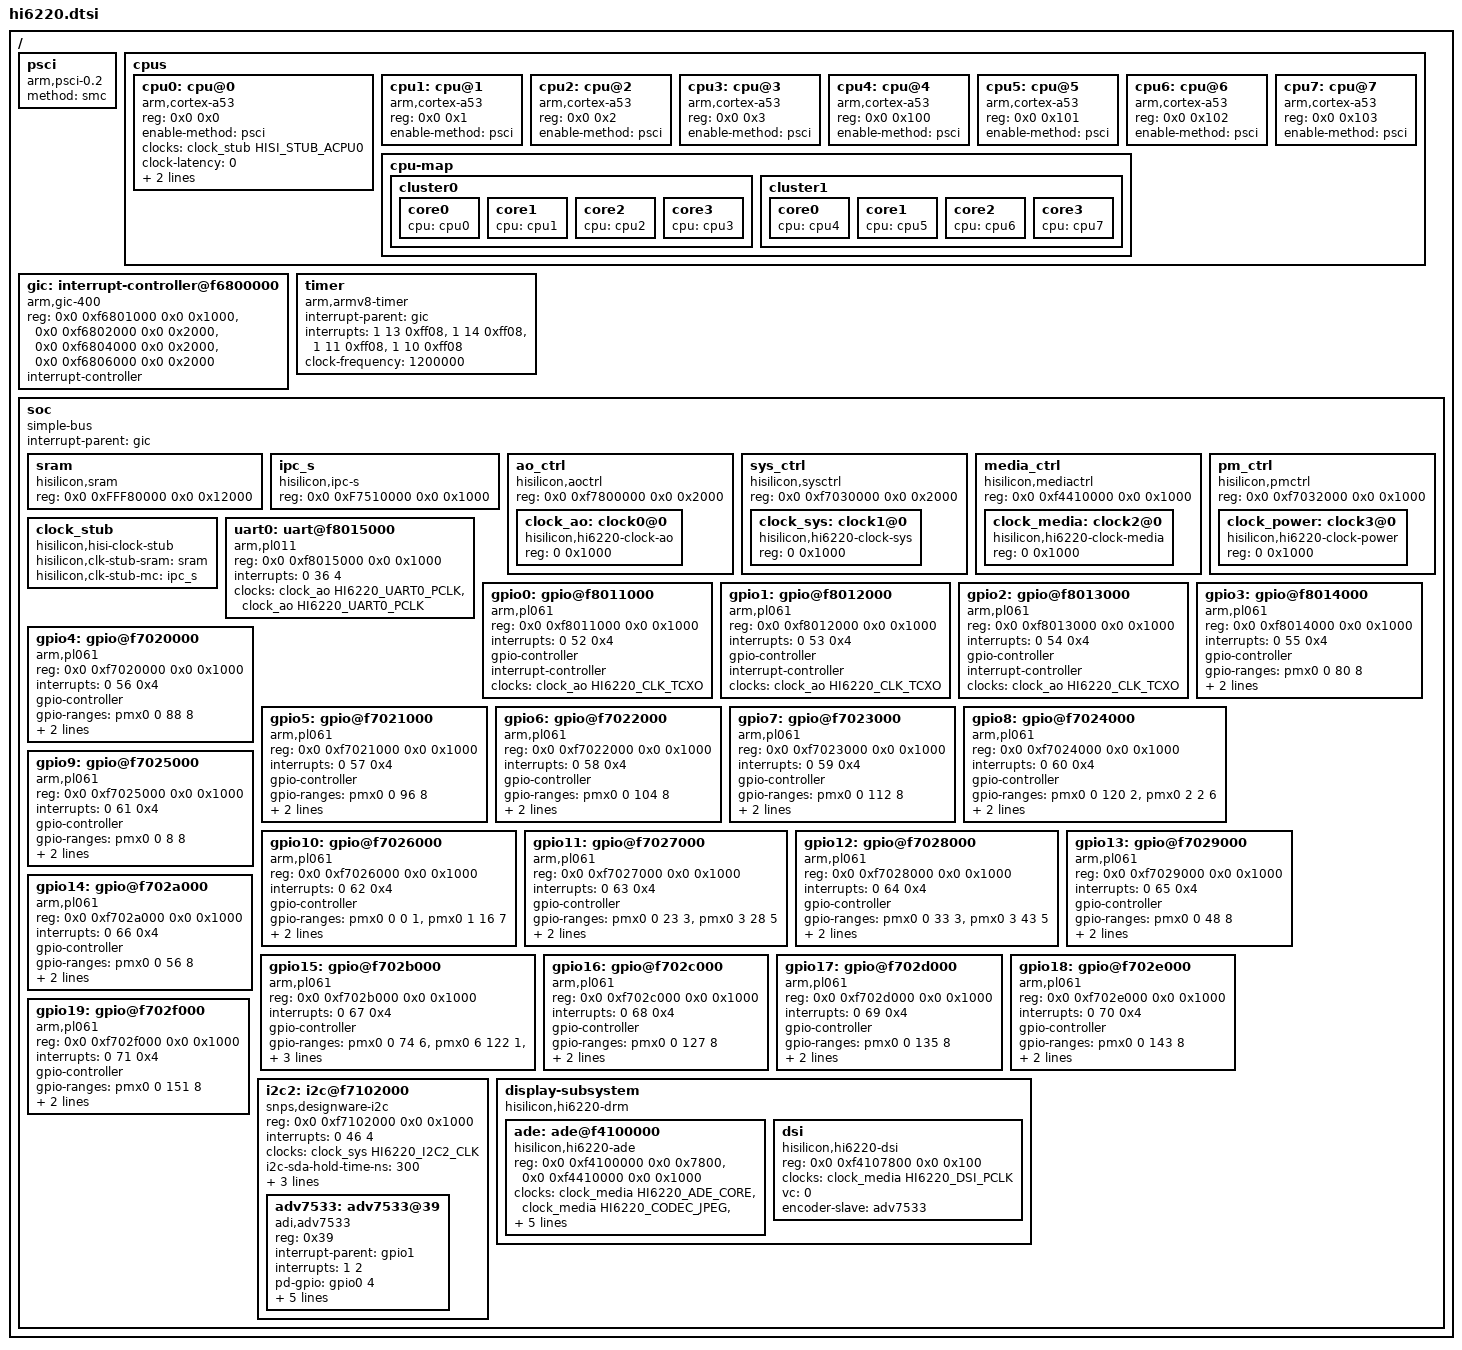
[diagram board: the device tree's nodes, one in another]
/*
 * dts file for Hisilicon Hi6220 SoC
 *
 * Copyright (C) 2015, Hisilicon Ltd.
 */

#include <dt-bindings/clock/hi6220-clock.h>

/ {
	psci {
		compatible = "arm,psci-0.2";
		method = "smc";
	};

	cpus {
		#address-cells = <2>;
		#size-cells = <0>;

		cpu0: cpu@0 {
			compatible = "arm,cortex-a53", "arm,armv8";
			device_type = "cpu";
			reg = <0x0 0x0>;
			enable-method = "psci";
			clocks = <&clock_stub HISI_STUB_ACPU0>;
			clock-latency = <0>;
			operating-points = <
				/* kHz */
				1200000  0
				960000   0
				729000   0
				432000   0
				208000   0
			>;
			#cooling-cells = <2>; /* min followed by max */
		};

		cpu1: cpu@1 {
			compatible = "arm,cortex-a53", "arm,armv8";
			device_type = "cpu";
			reg = <0x0 0x1>;
			enable-method = "psci";
		};

		cpu2: cpu@2 {
			compatible = "arm,cortex-a53", "arm,armv8";
			device_type = "cpu";
			reg = <0x0 0x2>;
			enable-method = "psci";
		};

		cpu3: cpu@3 {
			compatible = "arm,cortex-a53", "arm,armv8";
			device_type = "cpu";
			reg = <0x0 0x3>;
			enable-method = "psci";
		};

		cpu4: cpu@4 {
			compatible = "arm,cortex-a53", "arm,armv8";
			device_type = "cpu";
			reg = <0x0 0x100>;
			enable-method = "psci";
		};

		cpu5: cpu@5 {
			compatible = "arm,cortex-a53", "arm,armv8";
			device_type = "cpu";
			reg = <0x0 0x101>;
			enable-method = "psci";
		};

		cpu6: cpu@6 {
			compatible = "arm,cortex-a53", "arm,armv8";
			device_type = "cpu";
			reg = <0x0 0x102>;
			enable-method = "psci";
		};

		cpu7: cpu@7 {
			compatible = "arm,cortex-a53", "arm,armv8";
			device_type = "cpu";
			reg = <0x0 0x103>;
			enable-method = "psci";
		};

		cpu-map {
			cluster0 {
				core0 {
					cpu = <&cpu0>;
				};
				core1 {
					cpu = <&cpu1>;
				};
				core2 {
					cpu = <&cpu2>;
				};
				core3 {
					cpu = <&cpu3>;
				};
			};
			cluster1 {
				core0 {
					cpu = <&cpu4>;
				};
				core1 {
					cpu = <&cpu5>;
				};
				core2 {
					cpu = <&cpu6>;
				};
				core3 {
					cpu = <&cpu7>;
				};
			};
		};
	};

	gic: interrupt-controller@f6800000 {
		compatible = "arm,gic-400", "arm,cortex-a15-gic";
		reg = <0x0 0xf6801000 0x0 0x1000>, /* GICD */
		      <0x0 0xf6802000 0x0 0x2000>, /* GICC */
		      <0x0 0xf6804000 0x0 0x2000>, /* GICH */
		      <0x0 0xf6806000 0x0 0x2000>; /* GICV */
		#interrupt-cells = <3>;
		#address-cells = <0>;
		interrupt-controller;
	};


	timer {
		compatible = "arm,armv8-timer";
		interrupt-parent = <&gic>;
		interrupts = <1 13 0xff08>,
			     <1 14 0xff08>,
			     <1 11 0xff08>,
			     <1 10 0xff08>;
		clock-frequency = <1200000>;
	};

	soc {
		compatible = "simple-bus";
		#address-cells = <2>;
		#size-cells = <2>;
		interrupt-parent = <&gic>;
		ranges;

		sram: sram {
			compatible = "hisilicon,sram", "syscon";
			reg = <0x0 0xFFF80000 0x0 0x12000>;
		};

		ipc_s: ipc_s {
			compatible = "hisilicon,ipc-s", "syscon";
			reg = <0x0 0xF7510000 0x0 0x1000>;
		};

		ao_ctrl: ao_ctrl {
			compatible = "hisilicon,aoctrl", "syscon";
			#address-cells = <1>;
			#size-cells = <1>;
			reg = <0x0 0xf7800000 0x0 0x2000>;
			ranges = <0 0x0 0xf7800000 0x2000>;

			clock_ao: clock0@0 {
				compatible = "hisilicon,hi6220-clock-ao";
				reg = <0 0x1000>;
				#clock-cells = <1>;
			};
		};

		sys_ctrl: sys_ctrl {
			compatible = "hisilicon,sysctrl", "syscon";
			#address-cells = <1>;
			#size-cells = <1>;
			reg = <0x0 0xf7030000 0x0 0x2000>;
			ranges = <0 0x0 0xf7030000 0x2000>;

			clock_sys: clock1@0 {
				compatible = "hisilicon,hi6220-clock-sys";
				reg = <0 0x1000>;
				#clock-cells = <1>;
			};
		};

		media_ctrl: media_ctrl {
			compatible = "hisilicon,mediactrl", "syscon";
			#address-cells = <1>;
			#size-cells = <1>;
			reg = <0x0 0xf4410000 0x0 0x1000>;
			ranges = <0 0x0 0xf4410000 0x1000>;

			clock_media: clock2@0 {
				compatible = "hisilicon,hi6220-clock-media";
				reg = <0 0x1000>;
				#clock-cells = <1>;
			};
		};

		pm_ctrl: pm_ctrl {
			compatible = "hisilicon,pmctrl", "syscon";
			#address-cells = <1>;
			#size-cells = <1>;
			reg = <0x0 0xf7032000 0x0 0x1000>;
			ranges = <0 0x0 0xf7032000 0x1000>;

			clock_power: clock3@0 {
				compatible = "hisilicon,hi6220-clock-power";
				reg = <0 0x1000>;
				#clock-cells = <1>;
			};
		};

		clock_stub: clock_stub {
			compatible = "hisilicon,hisi-clock-stub";
			hisilicon,clk-stub-sram = <&sram>;
			hisilicon,clk-stub-mc = <&ipc_s>;
			#clock-cells = <1>;
		};

		uart0: uart@f8015000 {	/* console */
			compatible = "arm,pl011", "arm,primecell";
			reg = <0x0 0xf8015000 0x0 0x1000>;
			interrupts = <0 36 4>;
			clocks = <&clock_ao HI6220_UART0_PCLK>, <&clock_ao HI6220_UART0_PCLK>;
			clock-names = "uartclk", "apb_pclk";
		};

		gpio0: gpio@f8011000 {
			compatible = "arm,pl061", "arm,primecell";
			reg = <0x0 0xf8011000 0x0 0x1000>;
			interrupts = <0 52 0x4>;
			gpio-controller;
			#gpio-cells = <2>;
			interrupt-controller;
			#interrupt-cells = <2>;
			clocks = <&clock_ao HI6220_CLK_TCXO>;
			clock-names = "apb_pclk";
			status = "ok";
		};

		gpio1: gpio@f8012000 {
			compatible = "arm,pl061", "arm,primecell";
			reg = <0x0 0xf8012000 0x0 0x1000>;
			interrupts = <0 53 0x4>;
			gpio-controller;
			#gpio-cells = <2>;
			interrupt-controller;
			#interrupt-cells = <2>;
			clocks = <&clock_ao HI6220_CLK_TCXO>;
			clock-names = "apb_pclk";
			status = "ok";
		};

		gpio2: gpio@f8013000 {
			compatible = "arm,pl061", "arm,primecell";
			reg = <0x0 0xf8013000 0x0 0x1000>;
			interrupts = <0 54 0x4>;
			gpio-controller;
			#gpio-cells = <2>;
			interrupt-controller;
			#interrupt-cells = <2>;
			clocks = <&clock_ao HI6220_CLK_TCXO>;
			clock-names = "apb_pclk";
			status = "ok";
		};

		gpio3: gpio@f8014000 {
			compatible = "arm,pl061", "arm,primecell";
			reg = <0x0 0xf8014000 0x0 0x1000>;
			interrupts = <0 55 0x4>;
			gpio-controller;
			#gpio-cells = <2>;
			gpio-ranges = <&pmx0 0 80 8>;
			interrupt-controller;
			#interrupt-cells = <2>;
			clocks = <&clock_ao HI6220_CLK_TCXO>;
			clock-names = "apb_pclk";
			status = "ok";
		};

		gpio4: gpio@f7020000 {
			compatible = "arm,pl061", "arm,primecell";
			reg = <0x0 0xf7020000 0x0 0x1000>;
			interrupts = <0 56 0x4>;
			gpio-controller;
			#gpio-cells = <2>;
			gpio-ranges = <&pmx0 0 88 8>;
			interrupt-controller;
			#interrupt-cells = <2>;
			clocks = <&clock_ao HI6220_CLK_TCXO>;
			clock-names = "apb_pclk";
			status = "ok";
		};

		gpio5: gpio@f7021000 {
			compatible = "arm,pl061", "arm,primecell";
			reg = <0x0 0xf7021000 0x0 0x1000>;
			interrupts = <0 57 0x4>;
			gpio-controller;
			#gpio-cells = <2>;
			gpio-ranges = <&pmx0 0 96 8>;
			interrupt-controller;
			#interrupt-cells = <2>;
			clocks = <&clock_ao HI6220_CLK_TCXO>;
			clock-names = "apb_pclk";
			status = "ok";
		};

		gpio6: gpio@f7022000 {
			compatible = "arm,pl061", "arm,primecell";
			reg = <0x0 0xf7022000 0x0 0x1000>;
			interrupts = <0 58 0x4>;
			gpio-controller;
			#gpio-cells = <2>;
			gpio-ranges = <&pmx0 0 104 8>;
			interrupt-controller;
			#interrupt-cells = <2>;
			clocks = <&clock_ao HI6220_CLK_TCXO>;
			clock-names = "apb_pclk";
			status = "ok";
		};

		gpio7: gpio@f7023000 {
			compatible = "arm,pl061", "arm,primecell";
			reg = <0x0 0xf7023000 0x0 0x1000>;
			interrupts = <0 59 0x4>;
			gpio-controller;
			#gpio-cells = <2>;
			gpio-ranges = <&pmx0 0 112 8>;
			interrupt-controller;
			#interrupt-cells = <2>;
			clocks = <&clock_ao HI6220_CLK_TCXO>;
			clock-names = "apb_pclk";
			status = "ok";
		};

		gpio8: gpio@f7024000 {
			compatible = "arm,pl061", "arm,primecell";
			reg = <0x0 0xf7024000 0x0 0x1000>;
			interrupts = <0 60 0x4>;
			gpio-controller;
			#gpio-cells = <2>;
			gpio-ranges = <&pmx0 0 120 2 &pmx0 2 2 6>;
			interrupt-controller;
			#interrupt-cells = <2>;
			clocks = <&clock_ao HI6220_CLK_TCXO>;
			clock-names = "apb_pclk";
			status = "ok";
		};

		gpio9: gpio@f7025000 {
			compatible = "arm,pl061", "arm,primecell";
			reg = <0x0 0xf7025000 0x0 0x1000>;
			interrupts = <0 61 0x4>;
			gpio-controller;
			#gpio-cells = <2>;
			gpio-ranges = <&pmx0 0 8 8>;
			interrupt-controller;
			#interrupt-cells = <2>;
			clocks = <&clock_ao HI6220_CLK_TCXO>;
			clock-names = "apb_pclk";
			status = "ok";
		};

		gpio10: gpio@f7026000 {
			compatible = "arm,pl061", "arm,primecell";
			reg = <0x0 0xf7026000 0x0 0x1000>;
			interrupts = <0 62 0x4>;
			gpio-controller;
			#gpio-cells = <2>;
			gpio-ranges = <&pmx0 0 0 1 &pmx0 1 16 7>;
			interrupt-controller;
			#interrupt-cells = <2>;
			clocks = <&clock_ao HI6220_CLK_TCXO>;
			clock-names = "apb_pclk";
			status = "ok";
		};

		gpio11: gpio@f7027000 {
			compatible = "arm,pl061", "arm,primecell";
			reg = <0x0 0xf7027000 0x0 0x1000>;
			interrupts = <0 63 0x4>;
			gpio-controller;
			#gpio-cells = <2>;
			gpio-ranges = <&pmx0 0 23 3 &pmx0 3 28 5>;
			interrupt-controller;
			#interrupt-cells = <2>;
			clocks = <&clock_ao HI6220_CLK_TCXO>;
			clock-names = "apb_pclk";
			status = "ok";
		};

		gpio12: gpio@f7028000 {
			compatible = "arm,pl061", "arm,primecell";
			reg = <0x0 0xf7028000 0x0 0x1000>;
			interrupts = <0 64 0x4>;
			gpio-controller;
			#gpio-cells = <2>;
			gpio-ranges = <&pmx0 0 33 3 &pmx0 3 43 5>;
			interrupt-controller;
			#interrupt-cells = <2>;
			clocks = <&clock_ao HI6220_CLK_TCXO>;
			clock-names = "apb_pclk";
			status = "ok";
		};

		gpio13: gpio@f7029000 {
			compatible = "arm,pl061", "arm,primecell";
			reg = <0x0 0xf7029000 0x0 0x1000>;
			interrupts = <0 65 0x4>;
			gpio-controller;
			#gpio-cells = <2>;
			gpio-ranges = <&pmx0 0 48 8>;
			interrupt-controller;
			#interrupt-cells = <2>;
			clocks = <&clock_ao HI6220_CLK_TCXO>;
			clock-names = "apb_pclk";
			status = "ok";
		};

		gpio14: gpio@f702a000 {
			compatible = "arm,pl061", "arm,primecell";
			reg = <0x0 0xf702a000 0x0 0x1000>;
			interrupts = <0 66 0x4>;
			gpio-controller;
			#gpio-cells = <2>;
			gpio-ranges = <&pmx0 0 56 8>;
			interrupt-controller;
			#interrupt-cells = <2>;
			clocks = <&clock_ao HI6220_CLK_TCXO>;
			clock-names = "apb_pclk";
			status = "ok";
		};

		gpio15: gpio@f702b000 {
			compatible = "arm,pl061", "arm,primecell";
			reg = <0x0 0xf702b000 0x0 0x1000>;
			interrupts = <0 67 0x4>;
			gpio-controller;
			#gpio-cells = <2>;
			gpio-ranges = <
				&pmx0 0 74 6
				&pmx0 6 122 1
				&pmx0 7 126 1
			>;
			interrupt-controller;
			#interrupt-cells = <2>;
			clocks = <&clock_ao HI6220_CLK_TCXO>;
			clock-names = "apb_pclk";
			status = "ok";
		};

		gpio16: gpio@f702c000 {
			compatible = "arm,pl061", "arm,primecell";
			reg = <0x0 0xf702c000 0x0 0x1000>;
			interrupts = <0 68 0x4>;
			gpio-controller;
			#gpio-cells = <2>;
			gpio-ranges = <&pmx0 0 127 8>;
			interrupt-controller;
			#interrupt-cells = <2>;
			clocks = <&clock_ao HI6220_CLK_TCXO>;
			clock-names = "apb_pclk";
			status = "ok";
		};

		gpio17: gpio@f702d000 {
			compatible = "arm,pl061", "arm,primecell";
			reg = <0x0 0xf702d000 0x0 0x1000>;
			interrupts = <0 69 0x4>;
			gpio-controller;
			#gpio-cells = <2>;
			gpio-ranges = <&pmx0 0 135 8>;
			interrupt-controller;
			#interrupt-cells = <2>;
			clocks = <&clock_ao HI6220_CLK_TCXO>;
			clock-names = "apb_pclk";
			status = "ok";
		};

		gpio18: gpio@f702e000 {
			compatible = "arm,pl061", "arm,primecell";
			reg = <0x0 0xf702e000 0x0 0x1000>;
			interrupts = <0 70 0x4>;
			gpio-controller;
			#gpio-cells = <2>;
			gpio-ranges = <&pmx0 0 143 8>;
			interrupt-controller;
			#interrupt-cells = <2>;
			clocks = <&clock_ao HI6220_CLK_TCXO>;
			clock-names = "apb_pclk";
			status = "ok";
		};

		gpio19: gpio@f702f000 {
			compatible = "arm,pl061", "arm,primecell";
			reg = <0x0 0xf702f000 0x0 0x1000>;
			interrupts = <0 71 0x4>;
			gpio-controller;
			#gpio-cells = <2>;
			gpio-ranges = <&pmx0 0 151 8>;
			interrupt-controller;
			#interrupt-cells = <2>;
			clocks = <&clock_ao HI6220_CLK_TCXO>;
			clock-names = "apb_pclk";
			status = "ok";
		};
		i2c2: i2c@f7102000 {
			compatible = "snps,designware-i2c";
			#address-cells = <1>;
			#size-cells = <0>;
			reg = <0x0 0xf7102000 0x0 0x1000>;
			interrupts = <0 46 4>;

			clocks = <&clock_sys HI6220_I2C2_CLK>;
			clock-names = "clk_i2c2";
			i2c-sda-hold-time-ns = <300>;
			delay-reg = <0x0 0x0f8 0x0 4>;
			reset-controller-reg = <0x330 0x334 0x338 3>;
			pinctrl-names = "default";
			pinctrl-0 = <&i2c2_pmx_func &i2c2_cfg_func>;
			status = "ok";

			adv7533: adv7533@39 {
				compatible = "adi,adv7533";
				reg = <0x39>;
				interrupt-parent = <&gpio1>;
				interrupts = <1 2>;
				pd-gpio = <&gpio0 4 0>;
				adi,input-depth = <8>;
				adi,input-colorspace = "rgb";
				adi,input-clock = "1x";
				adi,clock-delay = <0>;
				adi,embedded-sync;
			};
		 };

		display-subsystem {
			compatible = "hisilicon,hi6220-drm";
			#address-cells = <2>;
			#size-cells = <2>;
			ranges;

			ade: ade@f4100000 {
				compatible = "hisilicon,hi6220-ade";
				reg = <0x0 0xf4100000 0x0 0x7800>,
				      <0x0 0xf4410000 0x0 0x1000>;
				reg-names = "ade_base",
					    "media_base";
				clocks = <&clock_media HI6220_ADE_CORE>,
					 <&clock_media HI6220_CODEC_JPEG>,
					 <&clock_media HI6220_ADE_PIX_SRC>,
					 <&clock_ao HI6220_PLL_SYS>,
					 <&clock_ao HI6220_PLL_SYS_MEDIA>;
				/*clock name*/
				clock-names  = "clk_ade_core",
					       "aclk_codec_jpeg_src",
					       "clk_ade_pix",
					       "clk_syspll_src",
					       "clk_medpll_src";
				 /*ade core clock rate*/
				ade_core_clk_rate = <360000000>;
				 /*media_noc clock rate*/
				media_noc_clk_rate = <288000000>;
			};

			dsi {
				#address-cells = <1>;
				#size-cells = <0>;
				compatible = "hisilicon,hi6220-dsi";
				reg = <0x0 0xf4107800 0x0 0x100>;
				clocks = <&clock_media  HI6220_DSI_PCLK>;
				clock-names = "pclk_dsi";
				vc = <0>;
				encoder-slave = <&adv7533>;
			};
		};

	};
};
